# AT32F415 register map
Vendor: Keil; Series: AT32F415; File version: 1.0
CPU: CM4 r0p1, little endian, no MPU, FPU, 4 interrupt priority bits
Registers are 32-bit, read-write, reset 0x0 unless marked. A register's access mark holds for its fields unless they carry their own. Offsets are from the block's base; [hi:lo] are bit positions; {n}, {i} and the like mark numbered series.

## SDIO1 — Secure digital input/output interface
Base 0x40018000
0x00 POWER — Bits 1:0 = PWRCTRL: Power supply control bits
  [1:0] PWRCTRL
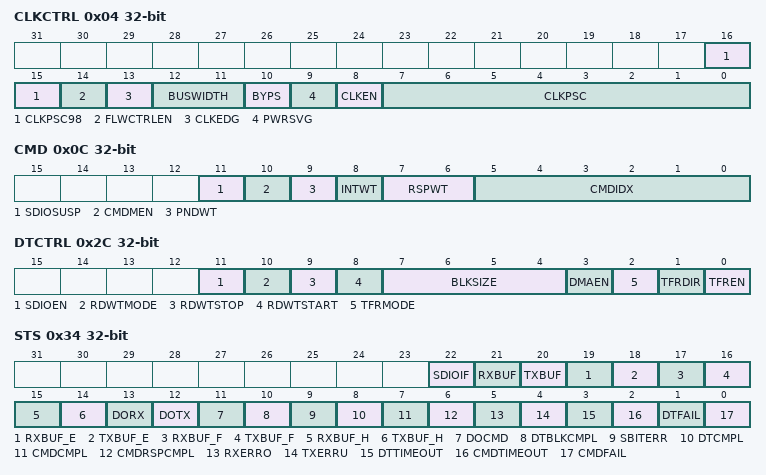
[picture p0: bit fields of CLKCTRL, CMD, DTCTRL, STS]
0x04 CLKCTRL — SDI clock control register (SDIO_CLKCTRL)
  [16:15] CLKPSC98 — Clock divide factor bit9 and bit8
  [14] FLWCTRLEN — HW Flow Control enable
  [13] CLKEDG — SDIO_CK dephasing selection bit
  [12:11] BUSWIDTH — Wide bus mode enable bit
  [10] BYPS — Clock divider bypass enable bit
  [9] PWRSVG — Power saving configuration bit
  [8] CLKEN — Clock enable bit
  [7:0] CLKPSC — Clock divide factor
0x08 ARG — Bits 31:0 = : Command argument
  [31:0] ARG — Command argument
0x0C CMD — SDIO command register (SDIO_CMD)
  [11] SDIOSUSP — SDIOSuspend
  [10] CMDMEN — CPSMEN
  [9] PNDWT — WAITPEND
  [8] INTWT — WAITINT
  [7:6] RSPWT — WAITRESP
  [5:0] CMDIDX
0x10 RSPCMD ro — SDIO command register
  [5:0] RSPCMD
{0x10+4i} RSP{i} ro (i=1..4) — Bits 31:0 = CARDSTATUS{i}
  [31:0] CARDSTS{i} — CARDSTATUS{i}
0x24 DTTMR — Bits 31:0 = DATATIME: Data timeout period
  [31:0] TIMEOUT — Data timeout period
0x28 DTLEN — Bits 24:0 = DATALENGTH: Data length value
  [24:0] DTLEN — Data length value
0x2C DTCTRL — SDIO data control register (SDIO_DCTRL)
  [11] SDIOEN
  [10] RDWTMODE — RWMOD
  [9] RDWTSTOP — PWSTOP
  [8] RDWTSTART — PWSTART
  [7:4] BLKSIZE — DBLOCKSIZE
  [3] DMAEN
  [2] TFRMODE — DTMODE
  [1] TFRDIR — DTDIR
  [0] TFREN — DTEN
0x30 DTCNTR ro — Bits 24:0 = DATACOUNT: Data count value
  [24:0] CNT — Data count value
0x34 STS ro — SDIO status register (SDIO_STS)
  [22] SDIOIF — SDIOIT
  [21] RXBUF — RXDAVL
  [20] TXBUF — TXDAVL
  [19] RXBUF_E — RXFIFOE
  [18] TXBUF_E — TXFIFOE
  [17] RXBUF_F — RXFIFOF
  [16] TXBUF_F — TXFIFOF
  [15] RXBUF_H — RXFIFOHF
  [14] TXBUF_H — TXFIFOHE
  [13] DORX — RXACT
  [12] DOTX — TXACT
  [11] DOCMD — CMDACT
  [10] DTBLKCMPL — DBCKEND
  [9] SBITERR — STBITERR
  [8] DTCMPL — DATAEND
  [7] CMDCMPL — CMDSENT
  [6] CMDRSPCMPL — CMDREND
  [5] RXERRO — RXOVERR
  [4] TXERRU — TXUNDERR
  [3] DTTIMEOUT — DTIMEOUT
  [2] CMDTIMEOUT — CTIMEOUT
  [1] DTFAIL — DCRCFAIL
  [0] CMDFAIL — CCRCFAIL
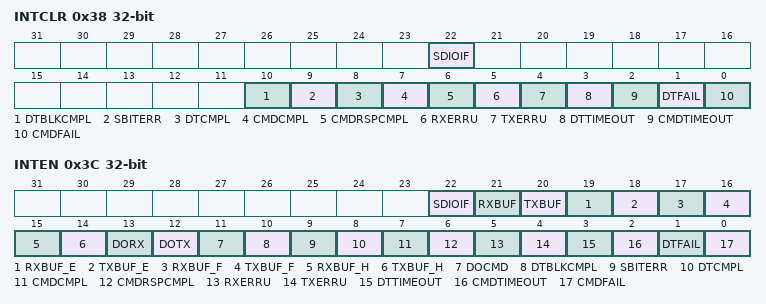
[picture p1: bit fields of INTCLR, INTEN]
0x38 INTCLR — SDIO interrupt clear register (SDIO_INTCLR)
  [22] SDIOIF — SDIOITC
  [10] DTBLKCMPL — DBCKENDC
  [9] SBITERR — STBITERRC
  [8] DTCMPL — DATAENDC
  [7] CMDCMPL — CMDSENTC
  [6] CMDRSPCMPL — CMDRENDC
  [5] RXERRU — RXOVERRC
  [4] TXERRU — TXUNDERRC
  [3] DTTIMEOUT — DTIMEOUTC
  [2] CMDTIMEOUT — CTIMEOUTC
  [1] DTFAIL — DCRCFAILC
  [0] CMDFAIL — CCRCFAILC
0x3C INTEN — SDIO interrupt enable register (SDIO_INTEN)
  [22] SDIOIF — SDIOITIE
  [21] RXBUF — RXDAVLIE
  [20] TXBUF — TXDAVLIE
  [19] RXBUF_E — RXFIFOEIE
  [18] TXBUF_E — TXFIFOEIE
  [17] RXBUF_F — RXFIFOFIE
  [16] TXBUF_F — TXFIFOFIE
  [15] RXBUF_H — RXFIFOHFIE
  [14] TXBUF_H — TXFIFOHEIE
  [13] DORX — RXACTIE
  [12] DOTX — TXACTIE
  [11] DOCMD — CMDACTIE
  [10] DTBLKCMPL — DBACKENDIE
  [9] SBITERR — STBITERRIE
  [8] DTCMPL — DATAENDIE
  [7] CMDCMPL — CMDSENTIE
  [6] CMDRSPCMPL — CMDRENDIE
  [5] RXERRU — RXOVERRIE
  [4] TXERRU — TXUNDERRIE
  [3] DTTIMEOUT — DTIMEOUTIE
  [2] CMDTIMEOUT — CTIMEOUTIE
  [1] DTFAIL — DCRCFAILIE
  [0] CMDFAIL — CCRCFAILIE
0x48 BUFCNTR ro — Bits 23:0 = FIFOCOUNT: Remaining number of words to be written to or read from the FIFO
  [23:0] CNT — FIF0COUNT
0x80 BUF — bits 31:0 = FIFOData: Receive and transmit FIFO data
  [31:0] DT — FIFOData

## WDT — Watchdog
Base 0x40003000
0x00 CMD — Command register
  [15:0] CMD
    0x5555=Unlock write-protected WDT_DIV and WDT_RLD; 0xAAAA=Reload counter; 0xCCCC=Enable WDT. If the hardware watchdog has been enabled, ignore this operation.
0x04 DIV — Division register
  [2:0] DIV — Division divider
    0=LICK divided by 4; 1=LICK divided by 8; 2=LICK divided by 16; 3=LICK divided by 32; 4=LICK divided by 64; 5=LICK divided by 128; 6=LICK divided by 256; 7=div256_2 (LICK divided by 256)
0x08 RLD reset 0xFFF — Reload register
  [11:0] RLD — Reload value
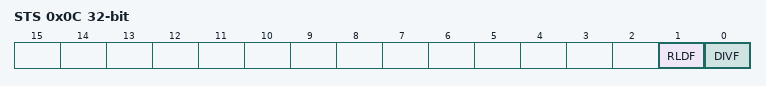
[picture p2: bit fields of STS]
0x0C STS ro — Status register
  [1] RLDF — Reload value update complete flag
    0=Complete (Reload value update complete); 1=InProgress (Reload value update is in process)
  [0] DIVF — Division value update complete flag
    0=Complete (Division value update complete); 1=InProgress (Division value update is in process)
